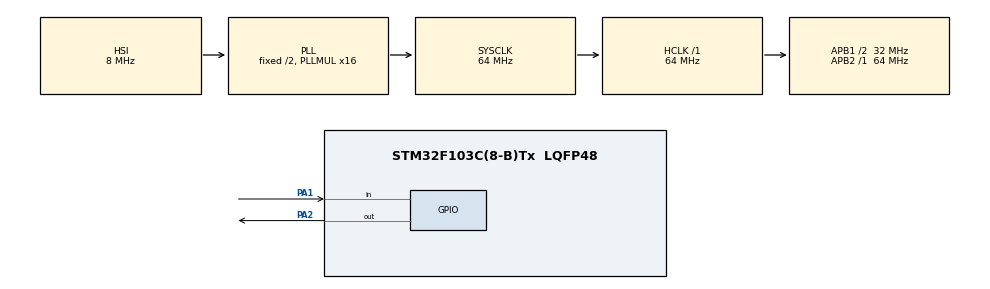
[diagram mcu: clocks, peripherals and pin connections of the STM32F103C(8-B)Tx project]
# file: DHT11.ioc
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Mcu.Family=STM32F1
Mcu.Name=STM32F103C(8-B)Tx
Mcu.Package=LQFP48
NVIC.PriorityGroup=NVIC_PRIORITYGROUP_4
NVIC.TIM1_UP_IRQn=true\:2\:0\:true\:false\:true\:true\:true\:true
PA1.Signal=GPIO_Input
PA13.Mode=Serial_Wire
PA13.Signal=SYS_JTMS-SWDIO
PA14.Mode=Serial_Wire
PA14.Signal=SYS_JTCK-SWCLK
PA2.Signal=GPIO_Output
PD0-OSC_IN.Mode=HSE-External-Oscillator
PD0-OSC_IN.Signal=RCC_OSC_IN
PD1-OSC_OUT.Mode=HSE-External-Oscillator
PD1-OSC_OUT.Signal=RCC_OSC_OUT
ProjectManager.HeapSize=0x200
ProjectManager.StackSize=0x400
ProjectManager.TargetToolchain=MDK-ARM V5.32
RCC.AHBFreq_Value=64000000
RCC.APB1CLKDivider=RCC_HCLK_DIV2
RCC.APB1Freq_Value=32000000
RCC.APB1TimFreq_Value=64000000
RCC.APB2Freq_Value=64000000
RCC.APB2TimFreq_Value=64000000
RCC.HCLKFreq_Value=64000000
RCC.PLLMUL=RCC_PLL_MUL16
RCC.SYSCLKFreq_VALUE=64000000
RCC.SYSCLKSource=RCC_SYSCLKSOURCE_PLLCLK
RCC.USBFreq_Value=64000000
TIM1.Period=499
TIM1.Prescaler=63999
TIM2.Prescaler=63
VP_TIM1_VS_ClockSourceINT.Mode=Internal
VP_TIM2_VS_ClockSourceINT.Mode=Internal
board=custom

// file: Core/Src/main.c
/* USER CODE BEGIN Header */
/**
  ******************************************************************************
  * @file           : main.c
  * @brief          : Main program body
  ******************************************************************************
  * @attention
  *
  * Copyright (c) 2026 STMicroelectronics.
  * All rights reserved.
  *
  * This software is licensed under terms that can be found in the LICENSE file
  * in the root directory of this software component.
  * If no LICENSE file comes with this software, it is provided AS-IS.
  *
  ******************************************************************************
  */
/* USER CODE END Header */
#include "main.h"

TIM_HandleTypeDef htim1;
TIM_HandleTypeDef htim2;

void SystemClock_Config(void);
static void MX_GPIO_Init(void);
static void MX_TIM1_Init(void);
static void MX_TIM2_Init(void);

/* USER CODE BEGIN 0 */
void HAL_TIM_PeriodElapsedCallback(TIM_HandleTypeDef *htim);
void delay_us(uint16_t time_us);
void delay_ms(uint16_t time_ms);
void setToOutput();
void setToInput();

void HAL_TIM_PeriodElapsedCallback(TIM_HandleTypeDef *htim) {

    if (htim->Instance == htim1.Instance) {
        HAL_GPIO_TogglePin(GPIOA, GPIO_PIN_1);
    }
}

void delay_us(uint16_t time_us) {

	HAL_TIM_Base_Start(&htim2);
  htim2.Instance->CNT = 0;
	while(htim2.Instance->CNT < time_us) {
	}
	HAL_TIM_Base_Stop(&htim2);

}

void delay_ms(uint16_t time_ms) {
   for(uint16_t i=0;i<time_ms;i++) {
		  delay_us(1000);
	 }
}

void setToOutput() {
	GPIO_InitTypeDef GPIO_InitStruct = {0};
	GPIO_InitStruct.Pin = GPIO_PIN_2;
  GPIO_InitStruct.Mode = GPIO_MODE_OUTPUT_PP;
  GPIO_InitStruct.Pull = GPIO_PULLUP;
  GPIO_InitStruct.Speed = GPIO_SPEED_FREQ_LOW;
  HAL_GPIO_Init(GPIOA, &GPIO_InitStruct);
}

void setToInput() {
	GPIO_InitTypeDef GPIO_InitStruct = {0};
	GPIO_InitStruct.Pin = GPIO_PIN_2;
  GPIO_InitStruct.Mode = GPIO_MODE_INPUT;
  GPIO_InitStruct.Pull = GPIO_NOPULL;
  HAL_GPIO_Init(GPIOA, &GPIO_InitStruct);
}

void DHT11_Init() {
	setToOutput();
	HAL_GPIO_WritePin(GPIOA,GPIO_PIN_2,1);
	HAL_GPIO_WritePin(GPIOA,GPIO_PIN_2,0);
	delay_ms(20);
	HAL_GPIO_WritePin(GPIOA,GPIO_PIN_2,1);
	setToInput();
  while(HAL_GPIO_ReadPin(GPIOA,GPIO_PIN_2) == 1) {} //doi = 0
	while(HAL_GPIO_ReadPin(GPIOA,GPIO_PIN_2) == 0) {} //doi = 1
	while(HAL_GPIO_ReadPin(GPIOA,GPIO_PIN_2) == 1) {} //doi = 0
}

uint8_t DHT11_WIRE_READ() {
	uint8_t ses = 0,i =0;
	for(i=0;i<8;i++) {
		while(HAL_GPIO_ReadPin(GPIOA,GPIO_PIN_2) == 0) {}
		delay_us(50);
		if(HAL_GPIO_ReadPin(GPIOA,GPIO_PIN_2) == 1) {
			//data = 1
			ses = (ses << 1) | (1 << 0);
		}else {
		   ses = (ses << 1) & ~(1 << 0);
		}
		while(HAL_GPIO_ReadPin(GPIOA,GPIO_PIN_2) == 1) {}
	}
  return ses;
}

uint8_t int_Tem = 0;
uint8_t int_Humi = 0;
uint8_t float_Tem = 0;
uint8_t float_Humi = 0;
uint8_t check_Sum = 0;

void DHT11_hendle() {
	 DHT11_Init();
	 int_Humi = DHT11_WIRE_READ();
	 float_Humi = DHT11_WIRE_READ();
	 int_Tem = DHT11_WIRE_READ();
	 float_Tem = DHT11_WIRE_READ();
	 check_Sum = DHT11_WIRE_READ();
}

/* USER CODE END 0 */

int main(void)
{

  /* MCU Configuration--------------------------------------------------------*/

  /* Reset of all peripherals, Initializes the Flash interface and the Systick. */
  HAL_Init();

  /* Configure the system clock */
  SystemClock_Config();

  /* Initialize all configured peripherals */
  MX_GPIO_Init();
  MX_TIM1_Init();
  MX_TIM2_Init();
  /* USER CODE BEGIN 2 */
  //HAL_TIM_Base_Start_IT(&htim1);
  /* USER CODE END 2 */

  /* Infinite loop */
  while (1)
  {
    DHT11_hendle();
		HAL_Delay(1000);
  }
}

void SystemClock_Config(void)
{
  RCC_OscInitTypeDef RCC_OscInitStruct = {0};
  RCC_ClkInitTypeDef RCC_ClkInitStruct = {0};

  /** Initializes the RCC Oscillators according to the specified parameters
  * in the RCC_OscInitTypeDef structure.
  */
  RCC_OscInitStruct.OscillatorType = RCC_OSCILLATORTYPE_HSI;
  RCC_OscInitStruct.HSIState = RCC_HSI_ON;
  RCC_OscInitStruct.HSICalibrationValue = RCC_HSICALIBRATION_DEFAULT;
  RCC_OscInitStruct.PLL.PLLState = RCC_PLL_ON;
  RCC_OscInitStruct.PLL.PLLSource = RCC_PLLSOURCE_HSI_DIV2;
  RCC_OscInitStruct.PLL.PLLMUL = RCC_PLL_MUL16;
  if (HAL_RCC_OscConfig(&RCC_OscInitStruct) != HAL_OK)
  {
    Error_Handler();
  }

  /** Initializes the CPU, AHB and APB buses clocks
  */
  RCC_ClkInitStruct.ClockType = RCC_CLOCKTYPE_HCLK|RCC_CLOCKTYPE_SYSCLK
                              |RCC_CLOCKTYPE_PCLK1|RCC_CLOCKTYPE_PCLK2;
  RCC_ClkInitStruct.SYSCLKSource = RCC_SYSCLKSOURCE_PLLCLK;
  RCC_ClkInitStruct.AHBCLKDivider = RCC_SYSCLK_DIV1;
  RCC_ClkInitStruct.APB1CLKDivider = RCC_HCLK_DIV2;
  RCC_ClkInitStruct.APB2CLKDivider = RCC_HCLK_DIV1;

  if (HAL_RCC_ClockConfig(&RCC_ClkInitStruct, FLASH_LATENCY_2) != HAL_OK)
  {
    Error_Handler();
  }
}

static void MX_TIM1_Init(void)
{

  TIM_ClockConfigTypeDef sClockSourceConfig = {0};
  TIM_MasterConfigTypeDef sMasterConfig = {0};

  htim1.Instance = TIM1;
  htim1.Init.Prescaler = 63999;
  htim1.Init.CounterMode = TIM_COUNTERMODE_UP;
  htim1.Init.Period = 499;
  htim1.Init.ClockDivision = TIM_CLOCKDIVISION_DIV1;
  htim1.Init.RepetitionCounter = 0;
  htim1.Init.AutoReloadPreload = TIM_AUTORELOAD_PRELOAD_DISABLE;
  if (HAL_TIM_Base_Init(&htim1) != HAL_OK)
  {
    Error_Handler();
  }
  sClockSourceConfig.ClockSource = TIM_CLOCKSOURCE_INTERNAL;
  if (HAL_TIM_ConfigClockSource(&htim1, &sClockSourceConfig) != HAL_OK)
  {
    Error_Handler();
  }
  sMasterConfig.MasterOutputTrigger = TIM_TRGO_RESET;
  sMasterConfig.MasterSlaveMode = TIM_MASTERSLAVEMODE_DISABLE;
  if (HAL_TIMEx_MasterConfigSynchronization(&htim1, &sMasterConfig) != HAL_OK)
  {
    Error_Handler();
  }

}

static void MX_TIM2_Init(void)
{

  TIM_ClockConfigTypeDef sClockSourceConfig = {0};
  TIM_MasterConfigTypeDef sMasterConfig = {0};

  htim2.Instance = TIM2;
  htim2.Init.Prescaler = 63;
  htim2.Init.CounterMode = TIM_COUNTERMODE_UP;
  htim2.Init.Period = 65535;
  htim2.Init.ClockDivision = TIM_CLOCKDIVISION_DIV1;
  htim2.Init.AutoReloadPreload = TIM_AUTORELOAD_PRELOAD_DISABLE;
  if (HAL_TIM_Base_Init(&htim2) != HAL_OK)
  {
    Error_Handler();
  }
  sClockSourceConfig.ClockSource = TIM_CLOCKSOURCE_INTERNAL;
  if (HAL_TIM_ConfigClockSource(&htim2, &sClockSourceConfig) != HAL_OK)
  {
    Error_Handler();
  }
  sMasterConfig.MasterOutputTrigger = TIM_TRGO_RESET;
  sMasterConfig.MasterSlaveMode = TIM_MASTERSLAVEMODE_DISABLE;
  if (HAL_TIMEx_MasterConfigSynchronization(&htim2, &sMasterConfig) != HAL_OK)
  {
    Error_Handler();
  }

}

static void MX_GPIO_Init(void)
{
  GPIO_InitTypeDef GPIO_InitStruct = {0};

  /* GPIO Ports Clock Enable */
  __HAL_RCC_GPIOD_CLK_ENABLE();
  __HAL_RCC_GPIOA_CLK_ENABLE();

  /*Configure GPIO pin Output Level */
  HAL_GPIO_WritePin(GPIOA, GPIO_PIN_2, GPIO_PIN_RESET);

  /*Configure GPIO pin : PA1 */
  GPIO_InitStruct.Pin = GPIO_PIN_1;
  GPIO_InitStruct.Mode = GPIO_MODE_INPUT;
  GPIO_InitStruct.Pull = GPIO_NOPULL;
  HAL_GPIO_Init(GPIOA, &GPIO_InitStruct);

  /*Configure GPIO pin : PA2 */
  GPIO_InitStruct.Pin = GPIO_PIN_2;
  GPIO_InitStruct.Mode = GPIO_MODE_OUTPUT_PP;
  GPIO_InitStruct.Pull = GPIO_NOPULL;
  GPIO_InitStruct.Speed = GPIO_SPEED_FREQ_LOW;
  HAL_GPIO_Init(GPIOA, &GPIO_InitStruct);

}

void Error_Handler(void)
{
  __disable_irq();
  while (1)
  {
  }
}
